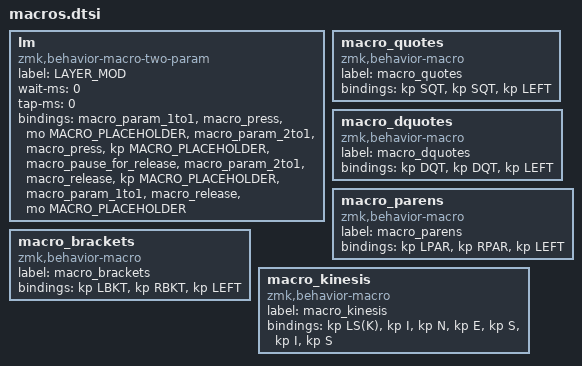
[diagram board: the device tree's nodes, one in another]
/**
* Temporarily switches to a layer (`&mo`) while a modifier is held.
* Analogous to QMK's `LM()`, using a parameterized macro.
*
* Params:
*  1. Layer to switch to
*  2. Modifier to press while layer is active
*
* Example:
*  `&lm NUM_LAYER LSHIFT`
*/
lm: lm {
    label = "LAYER_MOD";
    compatible = "zmk,behavior-macro-two-param";
    wait-ms = <0>;
    tap-ms = <0>;
    #binding-cells = <2>;
    bindings
        = <&macro_param_1to1>
        , <&macro_press &mo MACRO_PLACEHOLDER>
        , <&macro_param_2to1>
        , <&macro_press &kp MACRO_PLACEHOLDER>
        , <&macro_pause_for_release>
        , <&macro_param_2to1>
        , <&macro_release &kp MACRO_PLACEHOLDER>
        , <&macro_param_1to1>
        , <&macro_release &mo MACRO_PLACEHOLDER>
        ;
};

macro_quotes: macro_quotes{
    compatible = "zmk,behavior-macro";
    label = "macro_quotes";
    #binding-cells = <0>;
    bindings = <&kp SQT>, <&kp SQT>, <&kp LEFT>;
};

macro_dquotes: macro_dquotes{
    compatible = "zmk,behavior-macro";
    label = "macro_dquotes";
    #binding-cells = <0>;
    bindings = <&kp DQT>, <&kp DQT>, <&kp LEFT>;
};

macro_parens: macro_parens{
    compatible = "zmk,behavior-macro";
    label = "macro_parens";
    #binding-cells = <0>;
    bindings = <&kp LPAR>, <&kp RPAR>, <&kp LEFT>;
};

macro_brackets: macro_brackets{
    compatible = "zmk,behavior-macro";
    label = "macro_brackets";
    #binding-cells = <0>;
    bindings = <&kp LBKT>, <&kp RBKT>, <&kp LEFT>;
};

macro_kinesis: macro_kinesis{
    compatible = "zmk,behavior-macro";
    label = "macro_kinesis";
    #binding-cells = <0>;
    bindings = <&kp LS(K)>, <&kp I>, <&kp N>, <&kp E>, <&kp S>, <&kp I>, <&kp S>;
};
